VERSION "HIPBNYYYYYYYYYYYYYYYYYYYYYYYYYYYYYYYYYYYYY/4/%%%/4/'%**4YYY///"

NS_ :

BS_:

BU_: WS200 MCN_Powertrain

BO_ 1024 WS200IDInfo: 8 WS200
 SG_ TritiumID : 0|32@1+ (1,0) [0|0] "" Vector__XXX
 SG_ SerialNumber : 32|32@1+ (1,0) [0|0] "" Vector__XXX

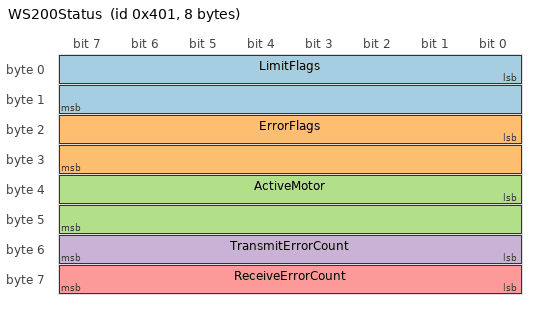
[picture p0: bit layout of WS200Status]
BO_ 1025 WS200Status: 8 WS200
 SG_ LimitFlags : 0|16@1+ (1,0) [0|0] "" Vector__XXX
 SG_ ErrorFlags : 16|16@1+ (1,0) [0|0] "" Vector__XXX
 SG_ ActiveMotor : 32|16@1+ (1,0) [0|0] "" Vector__XXX
 SG_ TransmitErrorCount : 48|8@1+ (1,0) [0|0] "" Vector__XXX
 SG_ ReceiveErrorCount : 56|8@1+ (1,0) [0|0] "" Vector__XXX

BO_ 1026 WS200BusMeasurement: 8 WS200
 SG_ BusVoltage : 0|32@1- (1,0) [0|0] "" Vector__XXX
 SG_ BusCurrent : 32|32@1- (1,0) [0|0] "" Vector__XXX

BO_ 1027 VelocityMeasurement: 8 WS200
 SG_ MotorVelocity : 0|32@1- (1,0) [0|0] "" Vector__XXX
 SG_ VehicleVelocity : 32|32@1- (1,0) [0|0] "" Vector__XXX

BO_ 1028 PhaseCurrent: 8 WS200
 SG_ PhaseCurrentB : 0|32@1- (1,0) [0|0] "" Vector__XXX
 SG_ PhaseCurrentC : 32|32@1- (1,0) [0|0] "" Vector__XXX

BO_ 1029 MotorVoltage: 8 WS200
 SG_ Vq : 0|32@1- (1,0) [0|0] "" Vector__XXX
 SG_ Vd : 32|32@1- (1,0) [0|0] "" Vector__XXX

BO_ 1030 MotorCurrent: 8 WS200
 SG_ Iq : 0|32@1- (1,0) [0|0] "" Vector__XXX
 SG_ Id : 32|32@1- (1,0) [0|0] "" Vector__XXX

BO_ 1031 MotorBackEMF: 8 WS200
 SG_ BEMFq : 0|32@1- (1,0) [0|0] "" Vector__XXX
 SG_ BEMFd : 32|32@1- (1,0) [0|0] "" Vector__XXX

BO_ 1032 WS200Rail15V: 8 WS200
 SG_ Supply15V : 32|32@1- (1,0) [0|0] "" Vector__XXX

BO_ 1033 WS200LowRail: 8 WS200
 SG_ Rail2V : 0|32@1- (1,0) [0|0] "" Vector__XXX
 SG_ Rail3V : 32|32@1- (1,0) [0|0] "" Vector__XXX

BO_ 994 DynoCoolantFlow: 4 MCN_Powertrain
 SG_ CoolantFlow : 0|32@1- (1,0) [0|0] "" Vector__XXX

BO_ 995 DynoMotorCoolantTemp: 4 MCN_Powertrain
 SG_ MotorCoolantTemp : 0|32@1- (1,0) [0|0] "" Vector__XXX

BO_ 996 DynoMotorControllerCoolantTemp: 4 MCN_Powertrain
 SG_ MotorControllerCoolantTemp : 0|32@1- (1,0) [0|0] "" Vector__XXX

BO_ 997 DynoRadiatorCoolantTemp: 4 MCN_Powertrain
 SG_ RadiatorCoolantTemp : 0|32@1- (1,0) [0|0] "" Vector__XXX

BO_ 998 DynoCoolantPressures: 8 MCN_Powertrain
 SG_ CoolantPressure1 : 0|32@1- (1,0) [0|0] "" Vector__XXX
 SG_ CoolantPressure2 : 32|32@1- (1,0) [0|0] "" Vector__XXX

BO_ 100 DynLoc: 8 Vector__XXX
 SG_ Speed : 0|32@1- (1,0) [0|0] "MPH" Vector__XXX
 SG_ Torque : 32|32@1- (1,0) [0|0] "Nm" Vector__XXX

BO_ 999 DynoMCNStatus: 8 MCN_Powertrain
 SG_ DynoMCNSystemFlags : 0|32@1+ (1,0) [0|0] "" Vector__XXX
 SG_ DynoMCNUserFlags : 32|32@1+ (1,0) [0|0] "" Vector__XXX

BO_ 992 DynoAmbientTemp: 4 MCN_Powertrain
 SG_ DynoMCNAmbientTemp : 0|32@1- (1,0) [0|0] "" Vector__XXX

BO_ 991 DynoMotorTemp: 4 MCN_Powertrain
 SG_ DynoMCNMotorTemp : 0|32@1- (1,0) [0|0] "" Vector__XXX

BO_ 993 DynoMotorPlateTemps: 8 MCN_Powertrain
 SG_ DynoMotorPlateTemp1 : 0|32@1- (1,0) [0|0] "" Vector__XXX
 SG_ DynoMotorPlateTemp2 : 32|32@1- (1,0) [0|0] "" Vector__XXX

BO_ 1035 WS200MotorTemp: 8 WS200
 SG_ IPMPhaseATemp : 32|32@1- (1,0) [0|0] "" Vector__XXX
 SG_ MotorTemp : 0|32@1- (1,0) [0|0] "" Vector__XXX

BO_ 1036 WS200DSPBoardTemp: 8 WS200
 SG_ IPMPhaseBTemp : 0|32@1- (1,0) [0|0] "" Vector__XXX
 SG_ DSPBoardTemp : 32|32@1- (1,0) [0|0] "" Vector__XXX

BO_ 1037 WS200PhaseCTemp: 8 WS200
 SG_ IMPPhaseCTemp : 32|32@1- (1,0) [0|0] "" Vector__XXX
 SG_ Reserved1 : 0|32@1- (1,0) [0|0] "" Vector__XXX

BO_ 1038 WS200BusAmpHours: 8 WS200
 SG_ DCBusAmpHours : 32|32@1- (1,0) [0|0] "" Vector__XXX
 SG_ Odometer : 0|32@1- (1,0) [0|0] "" Vector__XXX

BO_ 1047 WS200SlipSpeed: 8 WS200
 SG_ SlipSpeed : 0|32@1- (1,0) [0|0] "" Vector__XXX
 SG_ Reserved2 : 32|32@1- (1,0) [0|0] "" Vector__XXX

CM_ SG_ 1025 ActiveMotor "[0,10]";
CM_ SG_ 100 Speed "[-10,10]";
CM_ SG_ 100 Torque "[-20,50]";
SIG_VALTYPE_ 1026 BusVoltage : 1;
SIG_VALTYPE_ 1026 BusCurrent : 1;
SIG_VALTYPE_ 1027 MotorVelocity : 1;
SIG_VALTYPE_ 1027 VehicleVelocity : 1;
SIG_VALTYPE_ 1028 PhaseCurrentB : 1;
SIG_VALTYPE_ 1028 PhaseCurrentC : 1;
SIG_VALTYPE_ 1029 Vq : 1;
SIG_VALTYPE_ 1029 Vd : 1;
SIG_VALTYPE_ 1030 Iq : 1;
SIG_VALTYPE_ 1030 Id : 1;
SIG_VALTYPE_ 1031 BEMFq : 1;
SIG_VALTYPE_ 1031 BEMFd : 1;
SIG_VALTYPE_ 1032 Supply15V : 1;
SIG_VALTYPE_ 1033 Rail2V : 1;
SIG_VALTYPE_ 1033 Rail3V : 1;
SIG_VALTYPE_ 994 CoolantFlow : 1;
SIG_VALTYPE_ 995 MotorCoolantTemp : 1;
SIG_VALTYPE_ 996 MotorControllerCoolantTemp : 1;
SIG_VALTYPE_ 997 RadiatorCoolantTemp : 1;
SIG_VALTYPE_ 998 CoolantPressure1 : 1;
SIG_VALTYPE_ 998 CoolantPressure2 : 1;
SIG_VALTYPE_ 100 Speed : 1;
SIG_VALTYPE_ 100 Torque : 1;
SIG_VALTYPE_ 992 DynoMCNAmbientTemp : 1;
SIG_VALTYPE_ 991 DynoMCNMotorTemp : 1;
SIG_VALTYPE_ 993 DynoMotorPlateTemp1 : 1;
SIG_VALTYPE_ 993 DynoMotorPlateTemp2 : 1;
SIG_VALTYPE_ 1035 IPMPhaseATemp : 1;
SIG_VALTYPE_ 1035 MotorTemp : 1;
SIG_VALTYPE_ 1036 IPMPhaseBTemp : 1;
SIG_VALTYPE_ 1036 DSPBoardTemp : 1;
SIG_VALTYPE_ 1037 IMPPhaseCTemp : 1;
SIG_VALTYPE_ 1037 Reserved : 1;
SIG_VALTYPE_ 1038 DCBusAmpHours : 1;
SIG_VALTYPE_ 1038 Odometer : 1;
SIG_VALTYPE_ 1047 SlipSpeed : 1;
SIG_VALTYPE_ 1047 Reserved : 1;
